AUTOSAR XML (schema 00052)
package /WgresTrpCp
  client server interface ActuatorInterface
    operation Action: fire-and-forget=false
      arg intensity: type=uint32_t, direction=IN, server-argument-impl-policy=USE-ARGUMENT-TYPE
      arg return_value: type=uint32_t, direction=OUT, server-argument-impl-policy=USE-ARGUMENT-TYPE
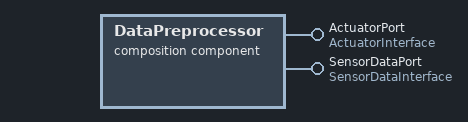
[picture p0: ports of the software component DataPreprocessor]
  composition sw component type DataPreprocessor
    provide port ActuatorPort: provided-interface=ActuatorInterface
    provide port SensorDataPort: provided-interface=SensorDataInterface
    component PostProcessorRef: type=PostProcessor
    component SensorProcessorRef: type=SensorProcessor
  application sw component type PostProcessor
    behavior ibPostProcessor
      runnable RunnableActionHandler
      runnable RunnableDriveActuator
      runnable RunnablePostProcessing
  sender receiver interface SensorDataInterface
    data SensorData: type=uint32_t
  application sw component type SensorProcessor
    behavior ibSensorProcessor
      operation invoked event oie_RunnableAction: start-on-event=RunnableActionHandler
      timing event te_RunnableSensorData: start-on-event=RunnableSendData, period=0.1
      4 x runnable:
        RunnableAdjustData
        RunnableFilterData
        RunnableReadSensor
        RunnableSendData
